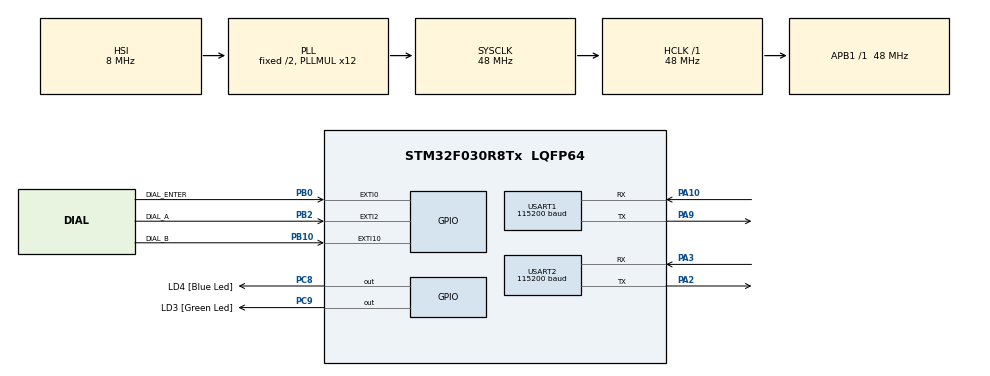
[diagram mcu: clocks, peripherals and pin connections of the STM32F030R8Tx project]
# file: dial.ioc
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Mcu.Family=STM32F0
Mcu.Name=STM32F030R8Tx
Mcu.Package=LQFP64
NVIC.EXTI0_1_IRQn=true\:0\:0\:false\:false\:true\:true\:true
NVIC.EXTI2_3_IRQn=true\:0\:0\:false\:false\:true\:true\:true
NVIC.EXTI4_15_IRQn=true\:0\:0\:false\:false\:true\:true\:true
NVIC.USART1_IRQn=true\:0\:0\:false\:false\:true\:true\:true
NVIC.USART2_IRQn=true\:0\:0\:false\:false\:true\:true\:true
PA10.Mode=Asynchronous
PA10.Signal=USART1_RX
PA13.GPIO_Label=SWDIO
PA13.Mode=Serial_Wire
PA13.Signal=SYS_SWDIO
PA14.GPIO_Label=SWCLK
PA14.Mode=Serial_Wire
PA14.Signal=SYS_SWCLK
PA2.Mode=Asynchronous
PA2.Signal=USART2_TX
PA3.Mode=Asynchronous
PA3.Signal=USART2_RX
PA9.Mode=Asynchronous
PA9.Signal=USART1_TX
PB0.GPIO_Label=DIAL_ENTER
PB0.GPIO_ModeDefaultEXTI=GPIO_MODE_IT_FALLING
PB0.Signal=GPXTI0
PB10.GPIO_Label=DIAL_B
PB10.GPIO_ModeDefaultEXTI=GPIO_MODE_IT_RISING_FALLING
PB10.Signal=GPXTI10
PB2.GPIO_Label=DIAL_A
PB2.GPIO_ModeDefaultEXTI=GPIO_MODE_IT_RISING_FALLING
PB2.Signal=GPXTI2
PC8.GPIO_Label=LD4 [Blue Led]
PC8.Signal=GPIO_Output
PC9.GPIO_Label=LD3 [Green Led]
PC9.Signal=GPIO_Output
ProjectManager.HeapSize=0x200
ProjectManager.StackSize=0x400
ProjectManager.TargetToolchain=TrueSTUDIO
RCC.AHBFreq_Value=48000000
RCC.APB1Freq_Value=48000000
RCC.APB1TimFreq_Value=48000000
RCC.HCLKFreq_Value=48000000
RCC.PLLMUL=RCC_PLL_MUL12
RCC.SYSCLKFreq_VALUE=48000000
RCC.SYSCLKSource=RCC_SYSCLKSOURCE_PLLCLK
USART1.BaudRate=115200
USART1.VirtualMode-Asynchronous=VM_ASYNC
USART2.BaudRate=115200
USART2.VirtualMode-Asynchronous=VM_ASYNC
board=32F0308DISCOVERY

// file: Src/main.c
/* USER CODE BEGIN Header */
/**
  ******************************************************************************
  * @file           : main.c
  * @brief          : Main program body
  ******************************************************************************
  * @attention
  *
  * <h2><center>&copy; Copyright (c) 2019 STMicroelectronics.
  * All rights reserved.</center></h2>
  *
  * This software component is licensed by ST under BSD 3-Clause license,
  * the "License"; You may not use this file except in compliance with the
  * License. You may obtain a copy of the License at:
  *                        opensource.org/licenses/BSD-3-Clause
  *
  ******************************************************************************
  */
/* USER CODE END Header */

#include "main.h"

/* USER CODE BEGIN Includes */
#include "dial_encoder.h"
#include "cuart.h"
/* USER CODE END Includes */

UART_HandleTypeDef huart1;
UART_HandleTypeDef huart2;

void SystemClock_Config(void);
static void MX_GPIO_Init(void);
static void MX_USART1_UART_Init(void);
static void MX_USART2_UART_Init(void);

int main(void)
{

  /* MCU Configuration--------------------------------------------------------*/

  /* Reset of all peripherals, Initializes the Flash interface and the Systick. */
  HAL_Init();

  /* USER CODE BEGIN Init */
  setvbuf(stdout, NULL, _IOLBF, 0);//_IONBF

  /* USER CODE END Init */

  /* Configure the system clock */
  SystemClock_Config();

  /* Initialize all configured peripherals */
  MX_GPIO_Init();
  MX_USART1_UART_Init();
  MX_USART2_UART_Init();
  /* USER CODE BEGIN 2 */

	dbg_setup();
	printf("program start\r\n");
  /* USER CODE END 2 */

  /* Infinite loop */
  while (1)
  {

    /* USER CODE BEGIN 3 */
	HAL_Delay(500);
	printf("looping \r\n");
    //dial_encoder_service();
  }
  /* USER CODE END 3 */
}

void SystemClock_Config(void)
{
  RCC_OscInitTypeDef RCC_OscInitStruct = {0};
  RCC_ClkInitTypeDef RCC_ClkInitStruct = {0};
  RCC_PeriphCLKInitTypeDef PeriphClkInit = {0};

  /** Initializes the CPU, AHB and APB busses clocks
  */
  RCC_OscInitStruct.OscillatorType = RCC_OSCILLATORTYPE_HSI;
  RCC_OscInitStruct.HSIState = RCC_HSI_ON;
  RCC_OscInitStruct.HSICalibrationValue = RCC_HSICALIBRATION_DEFAULT;
  RCC_OscInitStruct.PLL.PLLState = RCC_PLL_ON;
  RCC_OscInitStruct.PLL.PLLSource = RCC_PLLSOURCE_HSI;
  RCC_OscInitStruct.PLL.PLLMUL = RCC_PLL_MUL12;
  RCC_OscInitStruct.PLL.PREDIV = RCC_PREDIV_DIV1;
  if (HAL_RCC_OscConfig(&RCC_OscInitStruct) != HAL_OK)
  {
    Error_Handler();
  }
  /** Initializes the CPU, AHB and APB busses clocks
  */
  RCC_ClkInitStruct.ClockType = RCC_CLOCKTYPE_HCLK|RCC_CLOCKTYPE_SYSCLK
                              |RCC_CLOCKTYPE_PCLK1;
  RCC_ClkInitStruct.SYSCLKSource = RCC_SYSCLKSOURCE_PLLCLK;
  RCC_ClkInitStruct.AHBCLKDivider = RCC_SYSCLK_DIV1;
  RCC_ClkInitStruct.APB1CLKDivider = RCC_HCLK_DIV1;

  if (HAL_RCC_ClockConfig(&RCC_ClkInitStruct, FLASH_LATENCY_1) != HAL_OK)
  {
    Error_Handler();
  }
  PeriphClkInit.PeriphClockSelection = RCC_PERIPHCLK_USART1;
  PeriphClkInit.Usart1ClockSelection = RCC_USART1CLKSOURCE_PCLK1;
  if (HAL_RCCEx_PeriphCLKConfig(&PeriphClkInit) != HAL_OK)
  {
    Error_Handler();
  }
}

static void MX_USART1_UART_Init(void)
{

  huart1.Instance = USART1;
  huart1.Init.BaudRate = 115200;
  huart1.Init.WordLength = UART_WORDLENGTH_8B;
  huart1.Init.StopBits = UART_STOPBITS_1;
  huart1.Init.Parity = UART_PARITY_NONE;
  huart1.Init.Mode = UART_MODE_TX_RX;
  huart1.Init.HwFlowCtl = UART_HWCONTROL_NONE;
  huart1.Init.OverSampling = UART_OVERSAMPLING_16;
  huart1.Init.OneBitSampling = UART_ONE_BIT_SAMPLE_DISABLE;
  huart1.AdvancedInit.AdvFeatureInit = UART_ADVFEATURE_NO_INIT;
  if (HAL_UART_Init(&huart1) != HAL_OK)
  {
    Error_Handler();
  }

}

static void MX_USART2_UART_Init(void)
{

  huart2.Instance = USART2;
  huart2.Init.BaudRate = 115200;
  huart2.Init.WordLength = UART_WORDLENGTH_8B;
  huart2.Init.StopBits = UART_STOPBITS_1;
  huart2.Init.Parity = UART_PARITY_NONE;
  huart2.Init.Mode = UART_MODE_TX_RX;
  huart2.Init.HwFlowCtl = UART_HWCONTROL_NONE;
  huart2.Init.OverSampling = UART_OVERSAMPLING_16;
  huart2.Init.OneBitSampling = UART_ONE_BIT_SAMPLE_DISABLE;
  huart2.AdvancedInit.AdvFeatureInit = UART_ADVFEATURE_NO_INIT;
  if (HAL_UART_Init(&huart2) != HAL_OK)
  {
    Error_Handler();
  }

}

static void MX_GPIO_Init(void)
{
  GPIO_InitTypeDef GPIO_InitStruct = {0};

  /* GPIO Ports Clock Enable */
  __HAL_RCC_GPIOA_CLK_ENABLE();
  __HAL_RCC_GPIOB_CLK_ENABLE();
  __HAL_RCC_GPIOC_CLK_ENABLE();

  /*Configure GPIO pin Output Level */
  HAL_GPIO_WritePin(GPIOC, LD4_Pin|LD3_Pin, GPIO_PIN_RESET);

  /*Configure GPIO pin : DIAL_ENTER_Pin */
  GPIO_InitStruct.Pin = DIAL_ENTER_Pin;
  GPIO_InitStruct.Mode = GPIO_MODE_IT_FALLING;
  GPIO_InitStruct.Pull = GPIO_NOPULL;
  HAL_GPIO_Init(DIAL_ENTER_GPIO_Port, &GPIO_InitStruct);

  /*Configure GPIO pins : DIAL_A_Pin DIAL_B_Pin */
  GPIO_InitStruct.Pin = DIAL_A_Pin|DIAL_B_Pin;
  GPIO_InitStruct.Mode = GPIO_MODE_IT_RISING_FALLING;
  GPIO_InitStruct.Pull = GPIO_NOPULL;
  HAL_GPIO_Init(GPIOB, &GPIO_InitStruct);

  /*Configure GPIO pins : LD4_Pin LD3_Pin */
  GPIO_InitStruct.Pin = LD4_Pin|LD3_Pin;
  GPIO_InitStruct.Mode = GPIO_MODE_OUTPUT_PP;
  GPIO_InitStruct.Pull = GPIO_NOPULL;
  GPIO_InitStruct.Speed = GPIO_SPEED_FREQ_LOW;
  HAL_GPIO_Init(GPIOC, &GPIO_InitStruct);

  /* EXTI interrupt init*/
  HAL_NVIC_SetPriority(EXTI0_1_IRQn, 0, 0);
  HAL_NVIC_EnableIRQ(EXTI0_1_IRQn);

  HAL_NVIC_SetPriority(EXTI2_3_IRQn, 0, 0);
  HAL_NVIC_EnableIRQ(EXTI2_3_IRQn);

  HAL_NVIC_SetPriority(EXTI4_15_IRQn, 0, 0);
  HAL_NVIC_EnableIRQ(EXTI4_15_IRQn);

}

void Error_Handler(void)
{
}

/************************ (C) COPYRIGHT STMicroelectronics *****END OF FILE****/
